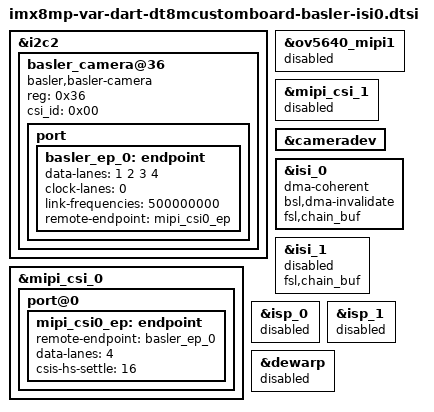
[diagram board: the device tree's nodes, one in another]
// SPDX-License-Identifier: (GPL-2.0+ OR MIT)
/*
 * Copyright 2019 NXP
 * Copyright 2020-2021 Variscite Ltd.
 */

&i2c2 {
	/delete-node/ov5640_mipi@3c;

	basler_camera@36 {
		compatible = "basler,basler-camera", "basler-camera";
		reg = <0x36>;
		csi_id = <0x00>;
		status = "okay";

		port {
			basler_ep_0: endpoint {
				data-lanes = <1 2 3 4>;
				clock-lanes = <0>;
				link-frequencies = /bits/ 64 <500000000>;
				remote-endpoint = <&mipi_csi0_ep>;
			};
		};
	};
};

&ov5640_mipi1 {
	status = "disabled";
};

&mipi_csi_0 {
	status = "okay";

	port@0 {
		mipi_csi0_ep: endpoint {
			remote-endpoint = <&basler_ep_0>;
			data-lanes = <4>;
			csis-hs-settle = <16>;
		};
	};
};

&mipi_csi_1 {
	status = "disabled";
};

&cameradev {
	status = "okay";
};

&isi_0 {
	status = "okay";
	dma-coherent;
	bsl,dma-invalidate;
	fsl,chain_buf;
};

&isi_1 {
	status = "disabled";
	fsl,chain_buf;
};

&isp_0 {
	status = "disabled";
};

&isp_1 {
	status = "disabled";
};

&dewarp {
	status = "disabled";
};
